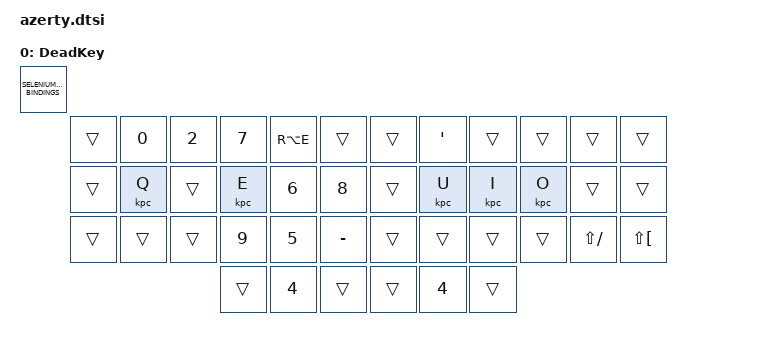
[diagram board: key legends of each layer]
#define DK_LAYER EXTRA_LAYERS_START_INDEX

&base_layer {
  display-name = "Base";
  bindings = <SELENIUM_KEYMAP_BINDINGS(
    &kp TAB     ,  &kp Q &kp W &kp E &kp R &kp T  ,  &kp Y  &kp U  &kp I     &kp O   &kp P     ,  &kp BACKSPACE    ,
    &kp ESCAPE  ,  HRM_A HRM_S HRM_D HRM_F &kp G  ,  &kp H  HRM_J  HRM_K     HRM_L   HRM_SEMI  ,  &EZ_SL(DK_LAYER) ,
    &kp LSHIFT  ,  &kp Z &kp X &kp C &kp V &kp B  ,  &kp N  &kp M  &kp COMMA &kp DOT &kp FSLH  ,  &kp RSHIFT       ,
        LTHUMB_TUCK , LTHUMB_HOME , LTHUMB_REACH  ,  RTHUMB_REACH , RTHUMB_HOME , RTHUMB_TUCK
  )>;
};

/ {
  behaviors {
    dead_key: dead_key {
      compatible = "zmk,behavior-mod-morph";
      #binding-cells = <0>;
      bindings = <&EZ_SL(DK_LAYER)>, <&kp SQT>;
      mods      = <(MOD_LSFT|MOD_RSFT)>;
      keep-mods = <(MOD_LSFT|MOD_RSFT)>;
    };
  };

  macros {
    DEAD_KEY(kpc, &kp LBKT)  // circumflex accent
  };

  // Extra layers defined specifically for this keymap, appended to the base keymap.
  keymap {
    compatible = "zmk,keymap";

    dead_key_layer {
      display-name = "DeadKey";
      bindings = <SELENIUM_KEYMAP_BINDINGS(
        &trans  ,  &kp N0  &kp N2  &kp N7  &kp RA(E) &trans   ,  &trans  &kp SQT &trans  &trans  &trans        ,  &trans,
        &trans  ,  &kpc Q  &trans  &kpc E  &kp N6  &kp N8     ,  &trans  &kpc U  &kpc I  &kpc O  &trans        ,  &trans,
        &trans  ,  &trans  &trans  &kp N9  &kp N5  &kp MINUS  ,  &trans  &trans  &trans  &trans  &kp LS(FSLH)  ,  &kp LS(LBKT),
                                    &trans , &kp N4 , &trans  ,  &trans , &kp N4 , &trans
      )>;
    };

  };
};
